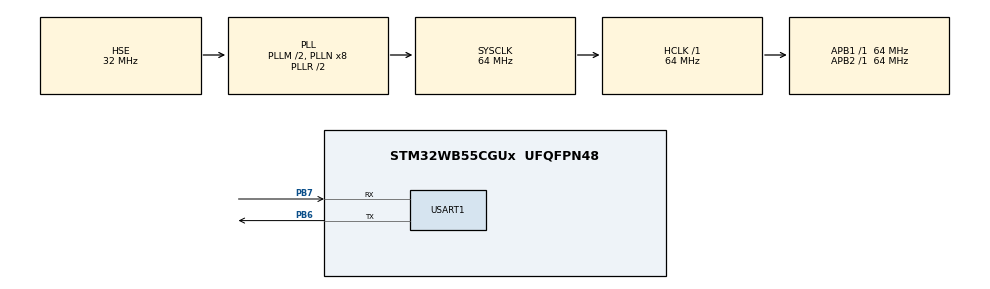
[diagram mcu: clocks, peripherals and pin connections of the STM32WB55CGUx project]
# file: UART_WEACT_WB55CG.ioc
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Mcu.Family=STM32WB
Mcu.Name=STM32WB55CGUx
Mcu.Package=UFQFPN48
NVIC.PriorityGroup=NVIC_PRIORITYGROUP_4
OSC_IN.Mode=HSE-External-Oscillator
OSC_IN.Signal=RCC_OSC_IN
OSC_OUT.Mode=HSE-External-Oscillator
OSC_OUT.Signal=RCC_OSC_OUT
PB6.Mode=Asynchronous
PB6.Signal=USART1_TX
PB7.Mode=Asynchronous
PB7.Signal=USART1_RX
PC14-OSC32_IN.Mode=LSE-External-Oscillator
PC14-OSC32_IN.Signal=RCC_OSC32_IN
PC15-OSC32_OUT.Mode=LSE-External-Oscillator
PC15-OSC32_OUT.Signal=RCC_OSC32_OUT
ProjectManager.HeapSize=0x200
ProjectManager.StackSize=0x400
ProjectManager.TargetToolchain=STM32CubeIDE
RCC.ADCFreq_Value=64000000
RCC.AHB2CLKDivider=RCC_SYSCLK_DIV2
RCC.AHBFreq_Value=64000000
RCC.APB1Freq_Value=64000000
RCC.APB1TimFreq_Value=64000000
RCC.APB2Freq_Value=64000000
RCC.APB2TimFreq_Value=64000000
RCC.APB3Freq_Value=16000000
RCC.Cortex2_Div=SYSTICK_CLKSOURCE_HCLK_DIV8
RCC.CortexFreq_Value=64000000
RCC.HCLKFreq_Value=64000000
RCC.HSE_VALUE=32000000
RCC.HSI48_VALUE=48000000
RCC.HSI_VALUE=16000000
RCC.PLLM=RCC_PLLM_DIV2
RCC.PLLSourceVirtual=RCC_PLLSOURCE_HSE
RCC.RTCClockSelection=RCC_RTCCLKSOURCE_LSE
RCC.SYSCLKFreq_VALUE=64000000
RCC.SYSCLKSource=RCC_SYSCLKSOURCE_PLLCLK
RCC.USBFreq_Value=64000000
RCC.VCOOutputFreq_Value=128000000
USART1.VirtualMode-Asynchronous=VM_ASYNC
VP_MEMORYMAP_VS_MEMORYMAP.Mode=CurAppReg
VP_RTC_VS_RTC_Activate.Mode=RTC_Enabled
board=custom

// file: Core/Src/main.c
/* USER CODE BEGIN Header */
/**
  ******************************************************************************
  * @file           : main.c
  * @brief          : Main program body
  ******************************************************************************
  * @attention
  *
  * Copyright (c) 2026 STMicroelectronics.
  * All rights reserved.
  *
  * This software is licensed under terms that can be found in the LICENSE file
  * in the root directory of this software component.
  * If no LICENSE file comes with this software, it is provided AS-IS.
  *
  ******************************************************************************
  */
/* USER CODE END Header */
#include "main.h"

/* USER CODE BEGIN Includes */
#include <stdio.h>
#include <string.h>
/* USER CODE END Includes */

RTC_HandleTypeDef hrtc;

UART_HandleTypeDef huart1;

/* USER CODE BEGIN PV */
uint8_t rx;
char linebuf[128];
uint32_t idx = 0;
/* USER CODE END PV */

void SystemClock_Config(void);
void PeriphCommonClock_Config(void);
static void MX_GPIO_Init(void);
static void MX_RTC_Init(void);
static void MX_USART1_UART_Init(void);

int main(void)
{

  /* MCU Configuration--------------------------------------------------------*/

  /* Reset of all peripherals, Initializes the Flash interface and the Systick. */
  HAL_Init();

  /* Configure the system clock */
  SystemClock_Config();

  /* Configure the peripherals common clocks */
  PeriphCommonClock_Config();

  /* Initialize all configured peripherals */
  MX_GPIO_Init();
  MX_RTC_Init();
  MX_USART1_UART_Init();
  /* USER CODE BEGIN 2 */
  printf("\r\n");
  printf("================================\r\n");
  printf("UART1 Echo Test Ready\r\n");
  printf("================================\r\n");
  /* USER CODE END 2 */

  /* Infinite loop */
  /* USER CODE BEGIN WHILE */
  while (1)
  {
	  if (HAL_UART_Receive(&huart1, &rx, 1, 10) == HAL_OK) {
	  		  if (rx == '\r' || rx == '\n') {
	  			  linebuf[idx] = '\0';

	  			  printf("\r\nEcho: %s\r\n", linebuf);
	  			  printf("> ");

	  			  idx = 0;
	  		  }
	  		  else {
	  			  if (idx < sizeof(linebuf) - 1) {
	  				  linebuf[idx++] = rx;

	  				  /* local echo supaya karakter muncul saat diketik */
	  				  printf("%c", rx);
	  			  }
	  		  }
	  	  }
    /* USER CODE END WHILE */

  }
}

void SystemClock_Config(void)
{
  RCC_OscInitTypeDef RCC_OscInitStruct = {0};
  RCC_ClkInitTypeDef RCC_ClkInitStruct = {0};

  /** Configure LSE Drive Capability
  */
  HAL_PWR_EnableBkUpAccess();
  __HAL_RCC_LSEDRIVE_CONFIG(RCC_LSEDRIVE_MEDIUMHIGH);

  /** Configure the main internal regulator output voltage
  */
  __HAL_PWR_VOLTAGESCALING_CONFIG(PWR_REGULATOR_VOLTAGE_SCALE1);

  /** Initializes the RCC Oscillators according to the specified parameters
  * in the RCC_OscInitTypeDef structure.
  */
  RCC_OscInitStruct.OscillatorType = RCC_OSCILLATORTYPE_HSI|RCC_OSCILLATORTYPE_HSE
                              |RCC_OSCILLATORTYPE_LSE;
  RCC_OscInitStruct.HSEState = RCC_HSE_ON;
  RCC_OscInitStruct.LSEState = RCC_LSE_ON;
  RCC_OscInitStruct.HSIState = RCC_HSI_ON;
  RCC_OscInitStruct.HSICalibrationValue = RCC_HSICALIBRATION_DEFAULT;
  RCC_OscInitStruct.PLL.PLLState = RCC_PLL_ON;
  RCC_OscInitStruct.PLL.PLLSource = RCC_PLLSOURCE_HSE;
  RCC_OscInitStruct.PLL.PLLM = RCC_PLLM_DIV2;
  RCC_OscInitStruct.PLL.PLLN = 8;
  RCC_OscInitStruct.PLL.PLLP = RCC_PLLP_DIV2;
  RCC_OscInitStruct.PLL.PLLR = RCC_PLLR_DIV2;
  RCC_OscInitStruct.PLL.PLLQ = RCC_PLLQ_DIV2;
  if (HAL_RCC_OscConfig(&RCC_OscInitStruct) != HAL_OK)
  {
    Error_Handler();
  }

  /** Configure the SYSCLKSource, HCLK, PCLK1 and PCLK2 clocks dividers
  */
  RCC_ClkInitStruct.ClockType = RCC_CLOCKTYPE_HCLK4|RCC_CLOCKTYPE_HCLK2
                              |RCC_CLOCKTYPE_HCLK|RCC_CLOCKTYPE_SYSCLK
                              |RCC_CLOCKTYPE_PCLK1|RCC_CLOCKTYPE_PCLK2;
  RCC_ClkInitStruct.SYSCLKSource = RCC_SYSCLKSOURCE_PLLCLK;
  RCC_ClkInitStruct.AHBCLKDivider = RCC_SYSCLK_DIV1;
  RCC_ClkInitStruct.APB1CLKDivider = RCC_HCLK_DIV1;
  RCC_ClkInitStruct.APB2CLKDivider = RCC_HCLK_DIV1;
  RCC_ClkInitStruct.AHBCLK2Divider = RCC_SYSCLK_DIV2;
  RCC_ClkInitStruct.AHBCLK4Divider = RCC_SYSCLK_DIV1;

  if (HAL_RCC_ClockConfig(&RCC_ClkInitStruct, FLASH_LATENCY_3) != HAL_OK)
  {
    Error_Handler();
  }
}

void PeriphCommonClock_Config(void)
{
  RCC_PeriphCLKInitTypeDef PeriphClkInitStruct = {0};

  /** Initializes the peripherals clock
  */
  PeriphClkInitStruct.PeriphClockSelection = RCC_PERIPHCLK_SMPS;
  PeriphClkInitStruct.SmpsClockSelection = RCC_SMPSCLKSOURCE_HSI;
  PeriphClkInitStruct.SmpsDivSelection = RCC_SMPSCLKDIV_RANGE1;

  if (HAL_RCCEx_PeriphCLKConfig(&PeriphClkInitStruct) != HAL_OK)
  {
    Error_Handler();
  }
}

static void MX_RTC_Init(void)
{

  /** Initialize RTC Only
  */
  hrtc.Instance = RTC;
  hrtc.Init.HourFormat = RTC_HOURFORMAT_24;
  hrtc.Init.AsynchPrediv = 127;
  hrtc.Init.SynchPrediv = 255;
  hrtc.Init.OutPut = RTC_OUTPUT_DISABLE;
  hrtc.Init.OutPutPolarity = RTC_OUTPUT_POLARITY_HIGH;
  hrtc.Init.OutPutType = RTC_OUTPUT_TYPE_OPENDRAIN;
  hrtc.Init.OutPutRemap = RTC_OUTPUT_REMAP_NONE;
  if (HAL_RTC_Init(&hrtc) != HAL_OK)
  {
    Error_Handler();
  }

}

static void MX_USART1_UART_Init(void)
{

  huart1.Instance = USART1;
  huart1.Init.BaudRate = 115200;
  huart1.Init.WordLength = UART_WORDLENGTH_8B;
  huart1.Init.StopBits = UART_STOPBITS_1;
  huart1.Init.Parity = UART_PARITY_NONE;
  huart1.Init.Mode = UART_MODE_TX_RX;
  huart1.Init.HwFlowCtl = UART_HWCONTROL_NONE;
  huart1.Init.OverSampling = UART_OVERSAMPLING_16;
  huart1.Init.OneBitSampling = UART_ONE_BIT_SAMPLE_DISABLE;
  huart1.Init.ClockPrescaler = UART_PRESCALER_DIV1;
  huart1.AdvancedInit.AdvFeatureInit = UART_ADVFEATURE_NO_INIT;
  if (HAL_UART_Init(&huart1) != HAL_OK)
  {
    Error_Handler();
  }
  if (HAL_UARTEx_SetTxFifoThreshold(&huart1, UART_TXFIFO_THRESHOLD_1_8) != HAL_OK)
  {
    Error_Handler();
  }
  if (HAL_UARTEx_SetRxFifoThreshold(&huart1, UART_RXFIFO_THRESHOLD_1_8) != HAL_OK)
  {
    Error_Handler();
  }
  if (HAL_UARTEx_DisableFifoMode(&huart1) != HAL_OK)
  {
    Error_Handler();
  }

}

static void MX_GPIO_Init(void)
{

  /* GPIO Ports Clock Enable */
  __HAL_RCC_GPIOC_CLK_ENABLE();
  __HAL_RCC_GPIOB_CLK_ENABLE();

}

void Error_Handler(void)
{
  __disable_irq();
  while (1)
  {
  }
}
